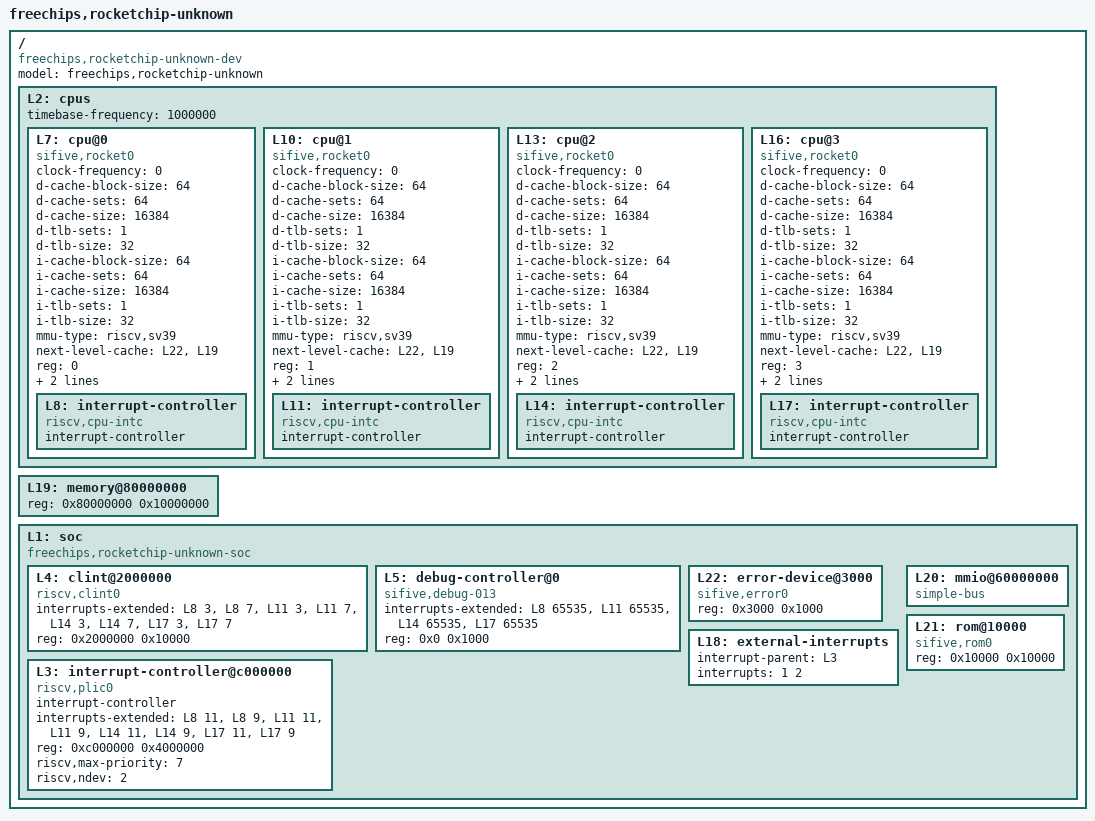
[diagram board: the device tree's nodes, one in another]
/dts-v1/;

/ {
	#address-cells = <1>;
	#size-cells = <1>;
	compatible = "freechips,rocketchip-unknown-dev";
	model = "freechips,rocketchip-unknown";
	L2: cpus {
		#address-cells = <1>;
		#size-cells = <0>;
		timebase-frequency = <1000000>;
		L7: cpu@0 {
			clock-frequency = <0>;
			compatible = "sifive,rocket0", "riscv";
			d-cache-block-size = <64>;
			d-cache-sets = <64>;
			d-cache-size = <16384>;
			d-tlb-sets = <1>;
			d-tlb-size = <32>;
			device_type = "cpu";
			i-cache-block-size = <64>;
			i-cache-sets = <64>;
			i-cache-size = <16384>;
			i-tlb-sets = <1>;
			i-tlb-size = <32>;
			mmu-type = "riscv,sv39";
			next-level-cache = <&L22 &L19>;
			reg = <0>;
			riscv,isa = "rv64imafdc";
			status = "okay";
			tlb-split;
			L8: interrupt-controller {
				#interrupt-cells = <1>;
				compatible = "riscv,cpu-intc";
				interrupt-controller;
			};
		};
		L10: cpu@1 {
			clock-frequency = <0>;
			compatible = "sifive,rocket0", "riscv";
			d-cache-block-size = <64>;
			d-cache-sets = <64>;
			d-cache-size = <16384>;
			d-tlb-sets = <1>;
			d-tlb-size = <32>;
			device_type = "cpu";
			i-cache-block-size = <64>;
			i-cache-sets = <64>;
			i-cache-size = <16384>;
			i-tlb-sets = <1>;
			i-tlb-size = <32>;
			mmu-type = "riscv,sv39";
			next-level-cache = <&L22 &L19>;
			reg = <1>;
			riscv,isa = "rv64imafdc";
			status = "okay";
			tlb-split;
			L11: interrupt-controller {
				#interrupt-cells = <1>;
				compatible = "riscv,cpu-intc";
				interrupt-controller;
			};
		};
		L13: cpu@2 {
			clock-frequency = <0>;
			compatible = "sifive,rocket0", "riscv";
			d-cache-block-size = <64>;
			d-cache-sets = <64>;
			d-cache-size = <16384>;
			d-tlb-sets = <1>;
			d-tlb-size = <32>;
			device_type = "cpu";
			i-cache-block-size = <64>;
			i-cache-sets = <64>;
			i-cache-size = <16384>;
			i-tlb-sets = <1>;
			i-tlb-size = <32>;
			mmu-type = "riscv,sv39";
			next-level-cache = <&L22 &L19>;
			reg = <2>;
			riscv,isa = "rv64imafdc";
			status = "okay";
			tlb-split;
			L14: interrupt-controller {
				#interrupt-cells = <1>;
				compatible = "riscv,cpu-intc";
				interrupt-controller;
			};
		};
		L16: cpu@3 {
			clock-frequency = <0>;
			compatible = "sifive,rocket0", "riscv";
			d-cache-block-size = <64>;
			d-cache-sets = <64>;
			d-cache-size = <16384>;
			d-tlb-sets = <1>;
			d-tlb-size = <32>;
			device_type = "cpu";
			i-cache-block-size = <64>;
			i-cache-sets = <64>;
			i-cache-size = <16384>;
			i-tlb-sets = <1>;
			i-tlb-size = <32>;
			mmu-type = "riscv,sv39";
			next-level-cache = <&L22 &L19>;
			reg = <3>;
			riscv,isa = "rv64imafdc";
			status = "okay";
			tlb-split;
			L17: interrupt-controller {
				#interrupt-cells = <1>;
				compatible = "riscv,cpu-intc";
				interrupt-controller;
			};
		};
	};
	L19: memory@80000000 {
		device_type = "memory";
		reg = <0x80000000 0x10000000>;
	};
	L1: soc {
		#address-cells = <1>;
		#size-cells = <1>;
		compatible = "freechips,rocketchip-unknown-soc", "simple-bus";
		ranges;
		L4: clint@2000000 {
			compatible = "riscv,clint0";
			interrupts-extended = <&L8 3 &L8 7 &L11 3 &L11 7 &L14 3 &L14 7 &L17 3 &L17 7>;
			reg = <0x2000000 0x10000>;
			reg-names = "control";
		};
		L5: debug-controller@0 {
			compatible = "sifive,debug-013", "riscv,debug-013";
			interrupts-extended = <&L8 65535 &L11 65535 &L14 65535 &L17 65535>;
			reg = <0x0 0x1000>;
			reg-names = "control";
		};
		L22: error-device@3000 {
			compatible = "sifive,error0";
			reg = <0x3000 0x1000>;
			reg-names = "mem";
		};
		L18: external-interrupts {
			interrupt-parent = <&L3>;
			interrupts = <1 2>;
		};
		L3: interrupt-controller@c000000 {
			#interrupt-cells = <1>;
			compatible = "riscv,plic0";
			interrupt-controller;
			interrupts-extended = <&L8 11 &L8 9 &L11 11 &L11 9 &L14 11 &L14 9 &L17 11 &L17 9>;
			reg = <0xc000000 0x4000000>;
			reg-names = "control";
			riscv,max-priority = <7>;
			riscv,ndev = <2>;
		};
		L20: mmio@60000000 {
			#address-cells = <1>;
			#size-cells = <1>;
			compatible = "simple-bus";
			ranges = <0x60000000 0x60000000 0x20000000>;
		};
		L21: rom@10000 {
			compatible = "sifive,rom0";
			reg = <0x10000 0x10000>;
			reg-names = "mem";
		};
	};
};
